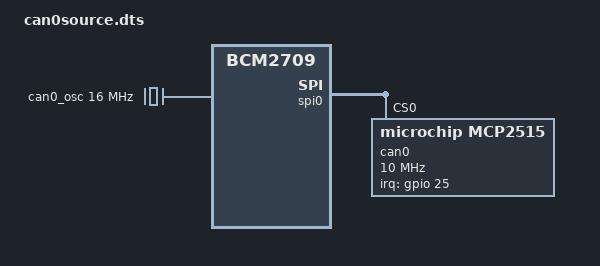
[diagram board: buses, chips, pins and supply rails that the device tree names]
/dts-v1/;
/plugin/;

/ {
    compatible = "brcm,bcm2835", "brcm,bcm2836", "brcm,bcm2708", "brcm,bcm2709";
    fragment@0 {
        target = <&spi0>;
        __overlay__ {
            status = "okay";
            spidev@0{
                status = "disabled";
            };
        };
    };

    fragment@1 {
        target = <&gpio>;
        __overlay__ {
            can0_pins: can0_pins {
                brcm,pins = <25>;
                brcm,function = <0>; /* input */
            };
        };
    };

    fragment@2 {
        target-path = "/clocks";
        __overlay__ {
            can0_osc: can0_osc {
                compatible = "fixed-clock";
                #clock-cells = <0>;
                clock-frequency  = <16000000>;
            };
        };
    };

    fragment@3 {
        target = <&spi0>;
        __overlay__ {
            #address-cells = <1>;
            #size-cells = <0>;
            can0: mcp2515@0 {
                reg = <0>;
                compatible = "microchip,mcp2515";
                pinctrl-names = "default";
                pinctrl-0 = <&can0_pins>;
                spi-max-frequency = <10000000>;
                interrupt-parent = <&gpio>;
                interrupts = <25 0x2>;
                clocks = <&can0_osc>;
            };
        };
    };
    __overrides__ {
        spimaxfrequency = <&can0>,"spi-max-frequency:0";
        interrupt = <&can0_pins>,"brcm,pins:0",<&can0>,"interrupts:0";
    };
};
